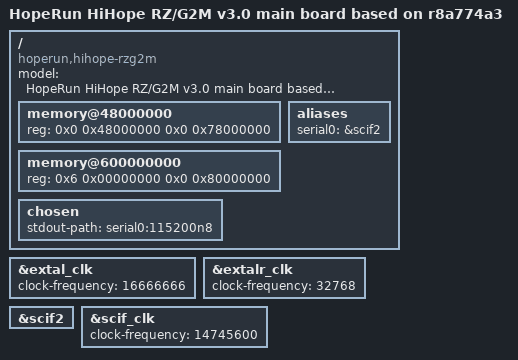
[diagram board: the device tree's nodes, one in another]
// SPDX-License-Identifier: GPL-2.0-only OR BSD-2-Clause
/*
 * Device Tree Source for the HiHope RZ/G2M v3.0 SoC main board
 *
 * Copyright (C) 2026 Renesas Electronics Corp.
 */

/dts-v1/;
#include "r8a774a3.dtsi"

/ {
	model = "HopeRun HiHope RZ/G2M v3.0 main board based on r8a774a3";
	compatible = "hoperun,hihope-rzg2m", "renesas,r8a774a3";

	memory@48000000 {
		device_type = "memory";
		/* First 128MiB is reserved for secure area */
		reg = <0x0 0x48000000 0x0 0x78000000>;
	};

	memory@600000000 {
		device_type = "memory";
		reg = <0x6 0x00000000 0x0 0x80000000>;
	};

	aliases {
		serial0 = &scif2;
	};

	chosen {
		stdout-path = "serial0:115200n8";
	};
};

&extal_clk {
	clock-frequency = <16666666>;
};

&extalr_clk {
	clock-frequency = <32768>;
};

&scif2 {
	status = "okay";
};

&scif_clk {
	clock-frequency = <14745600>;
};
